AUTOSAR XML (schema 4-3-0)
package /Impl_SWC_ETE_ARPkg
  swc implementation Impl_SWC_ETE_type: programming-language=C, sw-version=1.0.0, vendor-id=0, behavior=SWC_ETE_type_IB
    code-descriptors:
      code SRC: artifact-descriptors=autosar-engineering-object={short-label=EngObject, category=SWSRC}
    resource consumption ResourceConsumption
      memory section MEM_SWC_ETE_CODE: size=0, sw-addrmethod=CODE, symbol=CODE
      memory section MEM_SWC_ETE_CAL: size=0, sw-addrmethod=CAL, symbol=CAL
package /Interface_SWC_ETE_ARPkg/NewPackage
  trigger interface IF_Trig_FOC
    trigger Trig_FOC
package /SWC_ETE_ARPkg
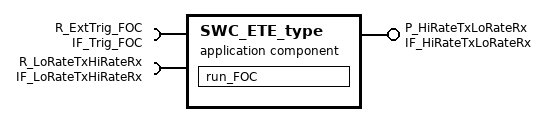
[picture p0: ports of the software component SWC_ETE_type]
  application sw component type SWC_ETE_type
    provide port P_HiRateTxLoRateRx: provided-interface=IF_HiRateTxLoRateRx
    require port R_ExtTrig_FOC: required-interface=IF_Trig_FOC
    require port R_LoRateTxHiRateRx: required-interface=IF_LoRateTxHiRateRx
    behavior SWC_ETE_type_IB: handle-termination-and-restart=NO-SUPPORT
      external trigger occurred event ETE_FOC: start-on-event=run_FOC, trigger=R_ExtTrig_FOC.Trig_FOC
      runnable run_FOC
        data-receive-point-by-arguments:
          access drparg_LoRateTxHiRateRx: accessed-variable=R_LoRateTxHiRateRx.LoRateTxHiRateRx
        data-send-points:
          access dsp_HiRateTxLoRateRx: accessed-variable=P_HiRateTxLoRateRx.HiRateTxLoRateRx
